# STM32F7x6 register map
File version: 1.3
CPU: CM7 r0p0, little endian, no MPU, no FPU, 3 interrupt priority bits
Registers are 32-bit, read-write, reset 0x0 unless marked. A register's access mark holds for its fields unless they carry their own. Offsets are from the block's base; [hi:lo] are bit positions; lines under a group give offsets from that group; {n}, {i} and the like mark numbered series.

## SYSCFG — System configuration controller
Base 0x40013800
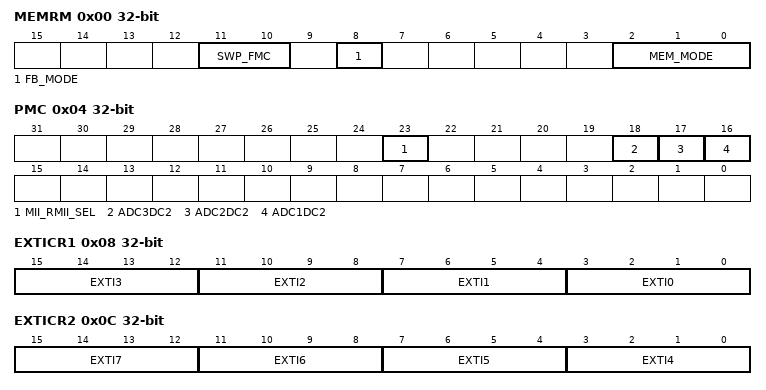
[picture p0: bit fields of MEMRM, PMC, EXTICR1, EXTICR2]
0x00 MEMRM — memory remap register
  [11:10] SWP_FMC — FMC memory mapping swap
  [8] FB_MODE — Flash bank mode selection
  [2:0] MEM_MODE — Memory mapping selection
0x04 PMC — peripheral mode configuration register
  [23] MII_RMII_SEL — Ethernet PHY interface selection
  [18] ADC3DC2
  [17] ADC2DC2
  [16] ADC1DC2
0x08 EXTICR1 — external interrupt configuration register 1
  [4n+3:4n] EXTI{n} (n=0..3) — EXTI x configuration (x = 0 to 3)
0x0C EXTICR2 — external interrupt configuration register 2
  [4n-13:4n-16] EXTI{n} (n=4..7) — EXTI x configuration (x = 4 to 7)
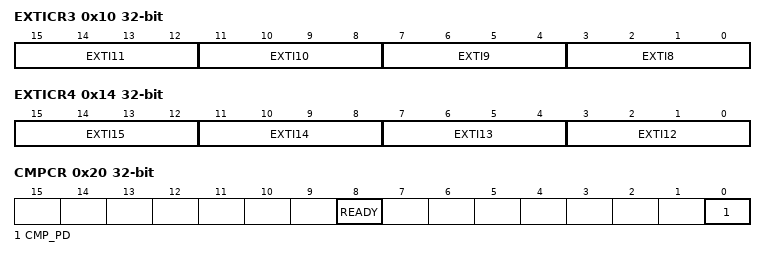
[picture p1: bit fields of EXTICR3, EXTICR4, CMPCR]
0x10 EXTICR3 — external interrupt configuration register 3
  [15:12] EXTI11 — EXTI x configuration (x = 8 to 11)
  [11:8] EXTI10
  [7:4] EXTI9 — EXTI x configuration (x = 8 to 11)
  [3:0] EXTI8 — EXTI x configuration (x = 8 to 11)
0x14 EXTICR4 — external interrupt configuration register 4
  [4n-45:4n-48] EXTI{n} (n=12..15) — EXTI x configuration (x = 12 to 15)
0x20 CMPCR ro — Compensation cell control register
  [8] READY
  [0] CMP_PD — Compensation cell power-down

## SPI1 — Serial peripheral interface
Base 0x40013000
Same registers: SPI2 0x40003800, SPI3 0x40003C00, SPI4 0x40013400, SPI5 0x40015000, SPI6 0x40015400
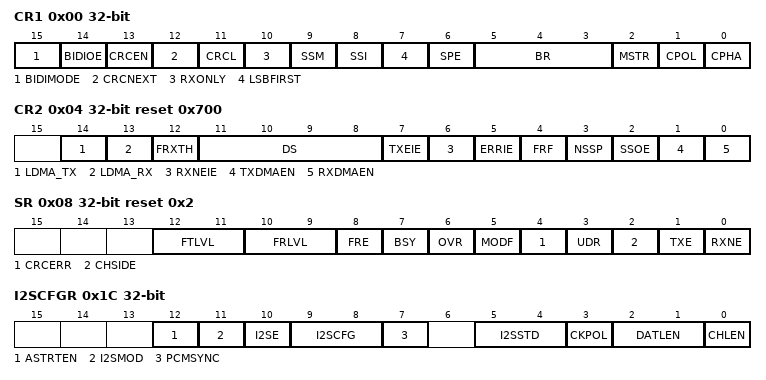
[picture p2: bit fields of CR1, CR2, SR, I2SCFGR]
0x00 CR1 — control register 1
  [15] BIDIMODE — Bidirectional data mode enable
  [14] BIDIOE — Output enable in bidirectional mode
  [13] CRCEN — Hardware CRC calculation enable
  [12] CRCNEXT — CRC transfer next
  [11] CRCL — CRC length
  [10] RXONLY — Receive only
  [9] SSM — Software slave management
  [8] SSI — Internal slave select
  [7] LSBFIRST — Frame format
  [6] SPE — SPI enable
  [5:3] BR — Baud rate control
  [2] MSTR — Master selection
  [1] CPOL — Clock polarity
  [0] CPHA — Clock phase
0x04 CR2 reset 0x700 — control register 2
  [14] LDMA_TX — Last DMA transfer for transmission
  [13] LDMA_RX — Last DMA transfer for reception
  [12] FRXTH — FIFO reception threshold
  [11:8] DS — Data size
  [7] TXEIE — Tx buffer empty interrupt enable
  [6] RXNEIE — RX buffer not empty interrupt enable
  [5] ERRIE — Error interrupt enable
  [4] FRF — Frame format
  [3] NSSP — NSS pulse management
  [2] SSOE — SS output enable
  [1] TXDMAEN — Tx buffer DMA enable
  [0] RXDMAEN — Rx buffer DMA enable
0x08 SR access per field reset 0x2 — status register
  [12:11] FTLVL ro — FIFO Transmission Level
  [10:9] FRLVL ro — FIFO reception level
  [8] FRE ro — Frame format error
  [7] BSY ro — Busy flag
  [6] OVR ro — Overrun flag
  [5] MODF ro — Mode fault
  [4] CRCERR rw — CRC error flag
  [3] UDR ro — Underrun flag
  [2] CHSIDE ro — Channel side
  [1] TXE ro — Transmit buffer empty
  [0] RXNE ro — Receive buffer not empty
0x0C DR — data register
  [15:0] DR — Data register
0x10 CRCPR reset 0x7 — CRC polynomial register
  [15:0] CRCPOLY
0x14 RXCRCR ro — RX CRC register
  [15:0] RxCRC
0x18 TXCRCR ro — TX CRC register
  [15:0] TxCRC
0x1C I2SCFGR — I2S configuration register
  [12] ASTRTEN — Asynchronous start enable
  [11] I2SMOD — I2S mode selection
  [10] I2SE — I2S Enable
  [9:8] I2SCFG — I2S configuration mode
  [7] PCMSYNC — PCM frame synchronization
  [5:4] I2SSTD — I2S standard selection
  [3] CKPOL — Steady state clock polarity
  [2:1] DATLEN — Data length to be transferred
  [0] CHLEN — Channel length (number of bits per audio channel)
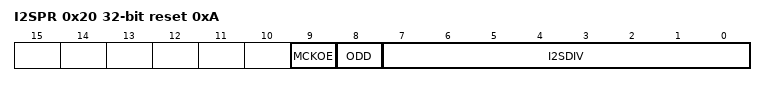
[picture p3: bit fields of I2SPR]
0x20 I2SPR reset 0xA — I2S prescaler register
  [9] MCKOE — Master clock output enable
  [8] ODD — Odd factor for the prescaler
  [7:0] I2SDIV — I2S Linear prescaler

## ADC1 — Analog-to-digital converter
Base 0x40012000
Same registers: ADC2 0x40012100, ADC3 0x40012200
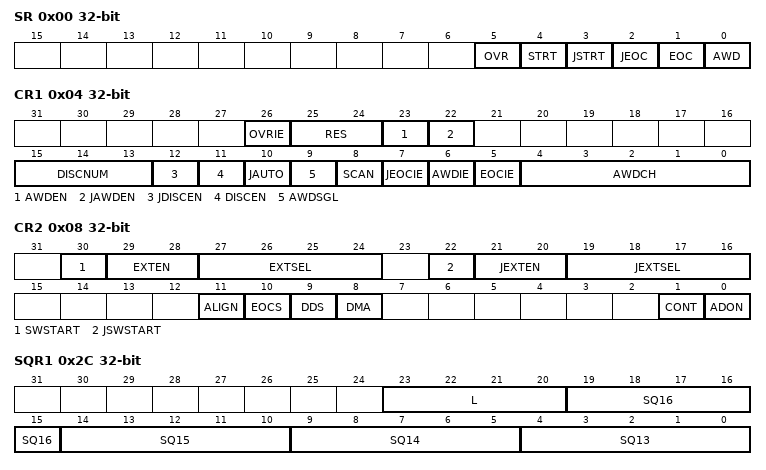
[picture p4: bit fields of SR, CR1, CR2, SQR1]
0x00 SR — status register
  [5] OVR — Overrun
  [4] STRT — Regular channel start flag
  [3] JSTRT — Injected channel start flag
  [2] JEOC — Injected channel end of conversion
  [1] EOC — Regular channel end of conversion
  [0] AWD — Analog watchdog flag
0x04 CR1 — control register 1
  [26] OVRIE — Overrun interrupt enable
  [25:24] RES — Resolution
  [23] AWDEN — Analog watchdog enable on regular channels
  [22] JAWDEN — Analog watchdog enable on injected channels
  [15:13] DISCNUM — Discontinuous mode channel count
  [12] JDISCEN — Discontinuous mode on injected channels
  [11] DISCEN — Discontinuous mode on regular channels
  [10] JAUTO — Automatic injected group conversion
  [9] AWDSGL — Enable the watchdog on a single channel in scan mode
  [8] SCAN — Scan mode
  [7] JEOCIE — Interrupt enable for injected channels
  [6] AWDIE — Analog watchdog interrupt enable
  [5] EOCIE — Interrupt enable for EOC
  [4:0] AWDCH — Analog watchdog channel select bits
0x08 CR2 — control register 2
  [30] SWSTART — Start conversion of regular channels
  [29:28] EXTEN — External trigger enable for regular channels
  [27:24] EXTSEL — External event select for regular group
  [22] JSWSTART — Start conversion of injected channels
  [21:20] JEXTEN — External trigger enable for injected channels
  [19:16] JEXTSEL — External event select for injected group
  [11] ALIGN — Data alignment
  [10] EOCS — End of conversion selection
  [9] DDS — DMA disable selection (for single ADC mode)
  [8] DMA — Direct memory access mode (for single ADC mode)
  [1] CONT — Continuous conversion
  [0] ADON — A/D Converter ON / OFF
0x0C SMPR1 — sample time register 1
  [31:0] SMPx_x — Sample time bits
0x10 SMPR2 — sample time register 2
  [31:0] SMPx_x — Sample time bits
{0x10+4i} JOFR{i} (i=1..4) — injected channel data offset register x
  [11:0] JOFFSET{i} — Data offset for injected channel x
0x24 HTR reset 0xFFF — watchdog higher threshold register
  [11:0] HT — Analog watchdog higher threshold
0x28 LTR — watchdog lower threshold register
  [11:0] LT — Analog watchdog lower threshold
0x2C SQR1 — regular sequence register 1
  [23:20] L — Regular channel sequence length
  [5n-61:5n-65] SQ{n} (n=13..16) — {n}th conversion in regular sequence
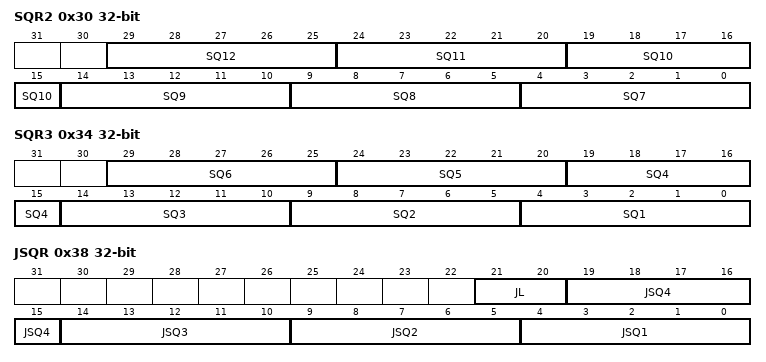
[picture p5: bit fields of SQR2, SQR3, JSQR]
0x30 SQR2 — regular sequence register 2
  [5n-31:5n-35] SQ{n} (n=7..12) — {n}th conversion in regular sequence
0x34 SQR3 — regular sequence register 3
  [29:25] SQ6 — 6th conversion in regular sequence
  [24:20] SQ5 — 5th conversion in regular sequence
  [19:15] SQ4 — 4th conversion in regular sequence
  [14:10] SQ3 — 3rd conversion in regular sequence
  [9:5] SQ2 — 2nd conversion in regular sequence
  [4:0] SQ1 — 1st conversion in regular sequence
0x38 JSQR — injected sequence register
  [21:20] JL — Injected sequence length
  [19:15] JSQ4 — 4th conversion in injected sequence
  [14:10] JSQ3 — 3rd conversion in injected sequence
  [9:5] JSQ2 — 2nd conversion in injected sequence
  [4:0] JSQ1 — 1st conversion in injected sequence
{0x38+4i} JDR{i} ro (i=1..4) — injected data register x
  [15:0] JDATA — Injected data
0x4C DR ro — regular data register
  [15:0] DATA — Regular data
